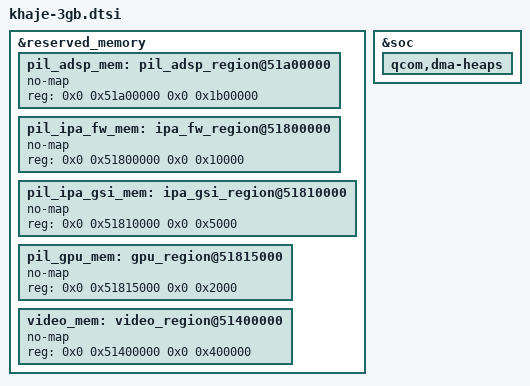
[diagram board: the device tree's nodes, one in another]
#include "khaje.dtsi"

&reserved_memory {

	/delete-node/ cdsp_sec_regions@46200000;
	/delete-node/ cdsp_regions@51a00000;
	/delete-node/ pil_adsp_region@53800000;
	/delete-node/ ipa_fw_region@55600000;
	/delete-node/ ipa_gsi_region@55610000;
	/delete-node/ gpu_region@55615000;
	/delete-node/ video_region@55617000;

	pil_adsp_mem: pil_adsp_region@51a00000 {
		no-map;
		reg = <0x0 0x51a00000 0x0 0x1b00000>;
	};

	pil_ipa_fw_mem: ipa_fw_region@51800000 {
		no-map;
		reg = <0x0 0x51800000 0x0 0x10000>;
	};

	pil_ipa_gsi_mem: ipa_gsi_region@51810000 {
		no-map;
		reg = <0x0 0x51810000 0x0 0x5000>;
	};

	pil_gpu_mem: gpu_region@51815000 {
		no-map;
		reg = <0x0 0x51815000 0x0 0x2000>;
	};

	video_mem: video_region@51400000 {
		no-map;
		reg = <0x0 0x51400000 0x0 0x400000>;
	};
};

&soc {
	/delete-node/ remoteproc-cdsp@b300000;
	/delete-node/ qcom,msm-cdsp-loader;

	qcom,dma-heaps {
		/delete-node/ qcom,secure_cdsp;
	};
};
